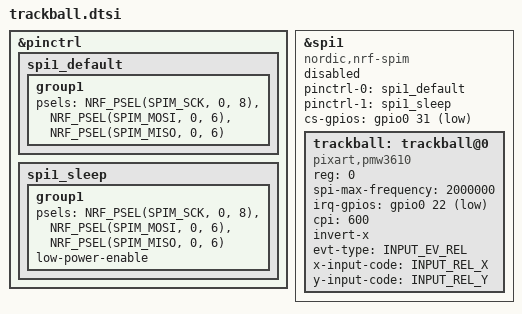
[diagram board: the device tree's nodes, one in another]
//================================================================
//   SPI-based trackball for peripheral side (right-hand / dongle)
//   Includes pinctrl setup and input device node.
//================================================================

&pinctrl {
    spi1_default: spi1_default { // Normal SPI operation pins
        group1 {
            psels = <NRF_PSEL(SPIM_SCK, 0, 8)>,
                    <NRF_PSEL(SPIM_MOSI, 0, 6)>,
                    <NRF_PSEL(SPIM_MISO, 0, 6)>;
        };
    };

    // Low-power SPI configuration for sleep mode
    spi1_sleep: spi1_sleep {
        group1 {
            psels = <NRF_PSEL(SPIM_SCK, 0, 8)>,
                    <NRF_PSEL(SPIM_MOSI, 0, 6)>,
                    <NRF_PSEL(SPIM_MISO, 0, 6)>;
            low-power-enable; // reduces power when idle
        };
    };
};

#include <zephyr/dt-bindings/input/input-event-codes.h>

&spi1 {                                     // input device node (SPI)
    status = "disabled";                    // keep SPI off by default
    compatible = "nordic,nrf-spim";
    pinctrl-0 = <&spi1_default>;            // default pins
    pinctrl-1 = <&spi1_sleep>;              // sleep pins
    pinctrl-names = "default", "sleep";
    cs-gpios = <&gpio0 31 GPIO_ACTIVE_LOW>; // chip select for SPI

    trackball: trackball@0 {
        status = "okay";
        compatible = "pixart,pmw3610";
        reg = <0>;                                                // first SPI slave device
        spi-max-frequency = <2000000>;                            // 2 MHz max SPI frequency
        irq-gpios = <&gpio0 22 (GPIO_ACTIVE_LOW | GPIO_PULL_UP)>; // interrupt pin
        cpi = <600>;                                              // trackball CPI
		// swap-xy;                                               // optional
        invert-x;                                                 // optional
        // invert-y;                                              // optional
        evt-type = <INPUT_EV_REL>;                                // relative motion events
        x-input-code = <INPUT_REL_X>;                             // X-axis movement
        y-input-code = <INPUT_REL_Y>;                             // Y-axis movement
    };
};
